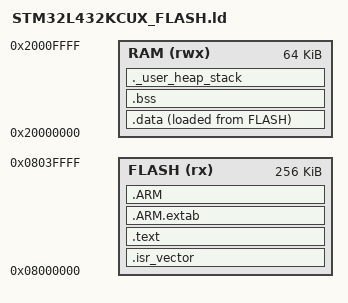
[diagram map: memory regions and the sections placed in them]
/*
 * STM32L432KCUX_FLASH.ld — linker script for STM32L432KC
 * Author: jayis1
 * Copyright (c) 2026 jayis1 — MIT License
 *
 * 256 kB flash at 0x08000000, 64 kB SRAM at 0x20000000.
 */

ENTRY(Reset_Handler)

MEMORY
{
    FLASH (rx) : ORIGIN = 0x08000000, LENGTH = 256K
    RAM   (rwx): ORIGIN = 0x20000000, LENGTH = 64K
}

_estack = ORIGIN(RAM) + LENGTH(RAM);

_Min_Heap_Size  = 0x200;
_Min_Stack_Size = 0x800;

SECTIONS
{
    .isr_vector :
    {
        . = ALIGN(4);
        KEEP(*(.isr_vector))
        . = ALIGN(4);
    } > FLASH

    .text :
    {
        . = ALIGN(4);
        *(.text)
        *(.text*)
        *(.rodata)
        *(.rodata*)
        . = ALIGN(4);
        _etext = .;
    } > FLASH

    .ARM.extab :
    {
        *(.ARM.extab* .gnu.linkonce.armextab.*)
    } > FLASH

    .ARM :
    {
        __exidx_start = .;
        *(.ARM.exidx*)
        __exidx_end = .;
    } > FLASH

    _sidata = LOADADDR(.data);
    .data :
    {
        . = ALIGN(4);
        _sdata = .;
        *(.data)
        *(.data*)
        . = ALIGN(4);
        _edata = .;
    } > RAM AT> FLASH

    .bss :
    {
        . = ALIGN(4);
        _sbss = .;
        *(.bss)
        *(.bss*)
        *(COMMON)
        . = ALIGN(4);
        _ebss = .;
    } > RAM

    ._user_heap_stack :
    {
        . = ALIGN(8);
        PROVIDE(end = .);
        PROVIDE(_end = .);
        . = . + _Min_Heap_Size;
        . = . + _Min_Stack_Size;
        . = ALIGN(8);
    } > RAM

    /DISCARD/ :
    {
        *(.ARM.attributes)
    }
}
